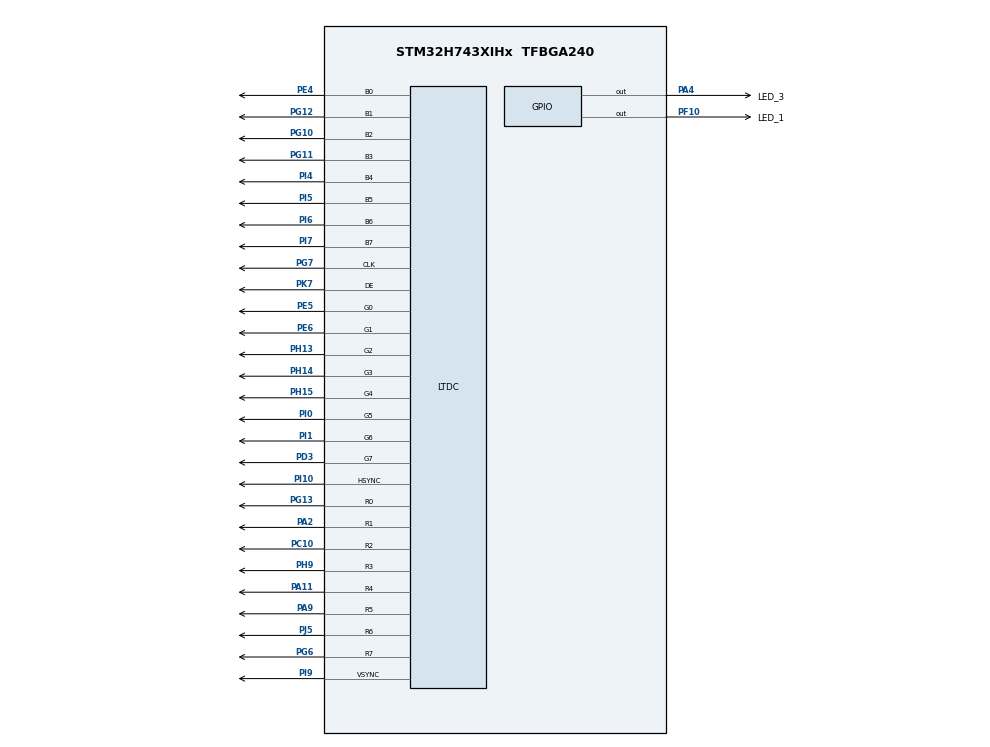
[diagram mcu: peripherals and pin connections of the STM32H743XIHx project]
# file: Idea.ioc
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FREERTOS.Tasks01=LED_1Blinker,1,128,StartBlinking1,Default,NULL,Dynamic,NULL,NULL;LED_3Blinker,0,128,StartBlinking3,Default,NULL,Dynamic,NULL,NULL;ResetLED,-1,128,StartReset,Default,NULL,Dynamic,NULL,NULL
FREERTOS.configENABLE_FPU=1
FREERTOS.configUSE_TIMERS=0
Mcu.Family=STM32H7
Mcu.Name=STM32H743XIHx
Mcu.Package=TFBGA240
NVIC.PriorityGroup=NVIC_PRIORITYGROUP_4
NVIC.TIM1_UP_IRQn=true\:15\:0\:false\:false\:true\:false\:false\:true\:true
NVIC.TimeBase=TIM1_UP_IRQn
NVIC.TimeBaseIP=TIM1
PA11.Mode=RGB888
PA11.Signal=LTDC_R4
PA2.Mode=RGB888
PA2.Signal=LTDC_R1
PA4.GPIO_Label=LED_3
PA4.Signal=GPIO_Output
PA9.Mode=RGB888
PA9.Signal=LTDC_R5
PC10.Mode=RGB888
PC10.Signal=LTDC_R2
PD3.Mode=RGB888
PD3.Signal=LTDC_G7
PE4.Mode=RGB888
PE4.Signal=LTDC_B0
PE5.Mode=RGB888
PE5.Signal=LTDC_G0
PE6.Mode=RGB888
PE6.Signal=LTDC_G1
PF10.GPIO_Label=LED_1
PF10.Signal=GPIO_Output
PG10.Mode=RGB888
PG10.Signal=LTDC_B2
PG11.Mode=RGB888
PG11.Signal=LTDC_B3
PG12.Mode=RGB888
PG12.Signal=LTDC_B1
PG13.Mode=RGB888
PG13.Signal=LTDC_R0
PG6.Mode=RGB888
PG6.Signal=LTDC_R7
PG7.Mode=RGB888
PG7.Signal=LTDC_CLK
PH13.Mode=RGB888
PH13.Signal=LTDC_G2
PH14.Mode=RGB888
PH14.Signal=LTDC_G3
PH15.Mode=RGB888
PH15.Signal=LTDC_G4
PH9.Mode=RGB888
PH9.Signal=LTDC_R3
PI0.Mode=RGB888
PI0.Signal=LTDC_G5
PI1.Mode=RGB888
PI1.Signal=LTDC_G6
PI10.Mode=RGB888
PI10.Signal=LTDC_HSYNC
PI4.Mode=RGB888
PI4.Signal=LTDC_B4
PI5.Mode=RGB888
PI5.Signal=LTDC_B5
PI6.Mode=RGB888
PI6.Signal=LTDC_B6
PI7.Mode=RGB888
PI7.Signal=LTDC_B7
PI9.Mode=RGB888
PI9.Signal=LTDC_VSYNC
PJ5.Mode=RGB888
PJ5.Signal=LTDC_R6
PK7.Mode=RGB888
PK7.Signal=LTDC_DE
ProjectManager.HeapSize=0x200
ProjectManager.StackSize=0x400
ProjectManager.TargetToolchain=STM32CubeIDE
RCC.ADCFreq_Value=75000000
RCC.APB1Freq_Value=75000000
RCC.APB2Freq_Value=18750000
RCC.APB3Freq_Value=75000000
RCC.APB4Freq_Value=75000000
RCC.CortexFreq_Value=75000000
RCC.D2PPRE2=RCC_APB2_DIV4
RCC.DIVM1=4
RCC.DIVM2=4
RCC.DIVM3=1
RCC.DIVN1=9
RCC.DIVN2=9
RCC.DIVN3=4
RCC.DIVQ1=1
RCC.HCLKFreq_Value=75000000
RCC.PLL2FRACN=3072
RCC.PLL3FRACN=0
RCC.PLLFRACN=3072
RCC.PWR_Regulator_Voltage_Scale=PWR_REGULATOR_VOLTAGE_SCALE1
RCC.SYSCLKFreq_VALUE=75000000
RCC.SYSCLKSource=RCC_SYSCLKSOURCE_PLLCLK
RCC.USBCLockSelection=RCC_USBCLKSOURCE_HSI48
RCC.USBFreq_Value=48000000
VP_FREERTOS_VS_CMSIS_V1.Mode=CMSIS_V1
VP_RNG_VS_RNG.Mode=RNG_Activate
VP_SYS_VS_tim1.Mode=TIM1
board=STM32H743I-EVAL2

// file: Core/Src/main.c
/* USER CODE BEGIN Header */
/**
  ******************************************************************************
  * @file           : main.c
  * @brief          : Main program body
  ******************************************************************************
  * @attention
  *
  * Copyright (c) 2023 STMicroelectronics.
  * All rights reserved.
  *
  * This software is licensed under terms that can be found in the LICENSE file
  * in the root directory of this software component.
  * If no LICENSE file comes with this software, it is provided AS-IS.
  *
  ******************************************************************************
  */
/* USER CODE END Header */
#include "main.h"
#include "cmsis_os.h"

LTDC_HandleTypeDef hltdc;

RNG_HandleTypeDef hrng;

osThreadId LED_1BlinkerHandle;
osThreadId LED_3BlinkerHandle;
osThreadId ResetLEDHandle;
osThreadId SetLEDHandle;

void SystemClock_Config(void);
static void MX_GPIO_Init(void);
static void MX_LTDC_Init(void);
static void MX_RNG_Init(void);
void StartBlinking1(void const * argument);
void StartBlinking3(void const * argument);
void StartReset(void const * argument);
void StartSet(void const * argument);

int main(void)
{

  /* MCU Configuration--------------------------------------------------------*/

  /* Reset of all peripherals, Initializes the Flash interface and the Systick. */
  HAL_Init();

  /* Configure the system clock */
  SystemClock_Config();

  /* Initialize all configured peripherals */
  MX_GPIO_Init();
  MX_LTDC_Init();
  MX_RNG_Init();

  /* Create the thread(s) */
  /* definition and creation of LED_1Blinker */
  osThreadDef(LED_1Blinker, StartBlinking1, osPriorityNormal, 0, 128);
  LED_1BlinkerHandle = osThreadCreate(osThread(LED_1Blinker), NULL);

  /* definition and creation of LED_3Blinker */
  osThreadDef(LED_3Blinker, StartBlinking3, osPriorityNormal, 0, 128);
  LED_3BlinkerHandle = osThreadCreate(osThread(LED_3Blinker), NULL);

  /* definition and creation of ResetLED */
  osThreadDef(ResetLED, StartReset, osPriorityBelowNormal, 0, 128);
  ResetLEDHandle = osThreadCreate(osThread(ResetLED), NULL);

  /* definition and creation of SetLED */
  osThreadDef(SetLED, StartSet, osPriorityBelowNormal, 0, 128);
  SetLEDHandle = osThreadCreate(osThread(SetLED), NULL);

  /* Start scheduler */
  osKernelStart();

  /* We should never get here as control is now taken by the scheduler */
  /* Infinite loop */
  while (1)
  {

  }
}

void SystemClock_Config(void)
{
  RCC_OscInitTypeDef RCC_OscInitStruct = {0};
  RCC_ClkInitTypeDef RCC_ClkInitStruct = {0};

  /** Supply configuration update enable
  */
  HAL_PWREx_ConfigSupply(PWR_LDO_SUPPLY);

  /** Configure the main internal regulator output voltage
  */
  __HAL_PWR_VOLTAGESCALING_CONFIG(PWR_REGULATOR_VOLTAGE_SCALE1);

  while(!__HAL_PWR_GET_FLAG(PWR_FLAG_VOSRDY)) {}

  /** Macro to configure the PLL clock source
  */
  __HAL_RCC_PLL_PLLSOURCE_CONFIG(RCC_PLLSOURCE_HSI);

  /** Initializes the RCC Oscillators according to the specified parameters
  * in the RCC_OscInitTypeDef structure.
  */
  RCC_OscInitStruct.OscillatorType = RCC_OSCILLATORTYPE_HSI48|RCC_OSCILLATORTYPE_HSI;
  RCC_OscInitStruct.HSIState = RCC_HSI_DIV1;
  RCC_OscInitStruct.HSICalibrationValue = RCC_HSICALIBRATION_DEFAULT;
  RCC_OscInitStruct.HSI48State = RCC_HSI48_ON;
  RCC_OscInitStruct.PLL.PLLState = RCC_PLL_ON;
  RCC_OscInitStruct.PLL.PLLSource = RCC_PLLSOURCE_HSI;
  RCC_OscInitStruct.PLL.PLLM = 4;
  RCC_OscInitStruct.PLL.PLLN = 9;
  RCC_OscInitStruct.PLL.PLLP = 2;
  RCC_OscInitStruct.PLL.PLLQ = 1;
  RCC_OscInitStruct.PLL.PLLR = 2;
  RCC_OscInitStruct.PLL.PLLRGE = RCC_PLL1VCIRANGE_3;
  RCC_OscInitStruct.PLL.PLLVCOSEL = RCC_PLL1VCOMEDIUM;
  RCC_OscInitStruct.PLL.PLLFRACN = 3072;
  if (HAL_RCC_OscConfig(&RCC_OscInitStruct) != HAL_OK)
  {
    Error_Handler();
  }

  /** Initializes the CPU, AHB and APB buses clocks
  */
  RCC_ClkInitStruct.ClockType = RCC_CLOCKTYPE_HCLK|RCC_CLOCKTYPE_SYSCLK
                              |RCC_CLOCKTYPE_PCLK1|RCC_CLOCKTYPE_PCLK2
                              |RCC_CLOCKTYPE_D3PCLK1|RCC_CLOCKTYPE_D1PCLK1;
  RCC_ClkInitStruct.SYSCLKSource = RCC_SYSCLKSOURCE_PLLCLK;
  RCC_ClkInitStruct.SYSCLKDivider = RCC_SYSCLK_DIV1;
  RCC_ClkInitStruct.AHBCLKDivider = RCC_HCLK_DIV1;
  RCC_ClkInitStruct.APB3CLKDivider = RCC_APB3_DIV1;
  RCC_ClkInitStruct.APB1CLKDivider = RCC_APB1_DIV1;
  RCC_ClkInitStruct.APB2CLKDivider = RCC_APB2_DIV4;
  RCC_ClkInitStruct.APB4CLKDivider = RCC_APB4_DIV1;

  if (HAL_RCC_ClockConfig(&RCC_ClkInitStruct, FLASH_LATENCY_1) != HAL_OK)
  {
    Error_Handler();
  }
}

static void MX_LTDC_Init(void)
{

  LTDC_LayerCfgTypeDef pLayerCfg = {0};
  LTDC_LayerCfgTypeDef pLayerCfg1 = {0};

  hltdc.Instance = LTDC;
  hltdc.Init.HSPolarity = LTDC_HSPOLARITY_AL;
  hltdc.Init.VSPolarity = LTDC_VSPOLARITY_AL;
  hltdc.Init.DEPolarity = LTDC_DEPOLARITY_AL;
  hltdc.Init.PCPolarity = LTDC_PCPOLARITY_IPC;
  hltdc.Init.HorizontalSync = 7;
  hltdc.Init.VerticalSync = 3;
  hltdc.Init.AccumulatedHBP = 14;
  hltdc.Init.AccumulatedVBP = 5;
  hltdc.Init.AccumulatedActiveW = 654;
  hltdc.Init.AccumulatedActiveH = 485;
  hltdc.Init.TotalWidth = 660;
  hltdc.Init.TotalHeigh = 487;
  hltdc.Init.Backcolor.Blue = 0;
  hltdc.Init.Backcolor.Green = 0;
  hltdc.Init.Backcolor.Red = 0;
  if (HAL_LTDC_Init(&hltdc) != HAL_OK)
  {
    Error_Handler();
  }
  pLayerCfg.WindowX0 = 0;
  pLayerCfg.WindowX1 = 0;
  pLayerCfg.WindowY0 = 0;
  pLayerCfg.WindowY1 = 0;
  pLayerCfg.PixelFormat = LTDC_PIXEL_FORMAT_ARGB8888;
  pLayerCfg.Alpha = 0;
  pLayerCfg.Alpha0 = 0;
  pLayerCfg.BlendingFactor1 = LTDC_BLENDING_FACTOR1_CA;
  pLayerCfg.BlendingFactor2 = LTDC_BLENDING_FACTOR2_CA;
  pLayerCfg.FBStartAdress = 0;
  pLayerCfg.ImageWidth = 0;
  pLayerCfg.ImageHeight = 0;
  pLayerCfg.Backcolor.Blue = 0;
  pLayerCfg.Backcolor.Green = 0;
  pLayerCfg.Backcolor.Red = 0;
  if (HAL_LTDC_ConfigLayer(&hltdc, &pLayerCfg, 0) != HAL_OK)
  {
    Error_Handler();
  }
  pLayerCfg1.WindowX0 = 0;
  pLayerCfg1.WindowX1 = 0;
  pLayerCfg1.WindowY0 = 0;
  pLayerCfg1.WindowY1 = 0;
  pLayerCfg1.PixelFormat = LTDC_PIXEL_FORMAT_ARGB8888;
  pLayerCfg1.Alpha = 0;
  pLayerCfg1.Alpha0 = 0;
  pLayerCfg1.BlendingFactor1 = LTDC_BLENDING_FACTOR1_CA;
  pLayerCfg1.BlendingFactor2 = LTDC_BLENDING_FACTOR2_CA;
  pLayerCfg1.FBStartAdress = 0;
  pLayerCfg1.ImageWidth = 0;
  pLayerCfg1.ImageHeight = 0;
  pLayerCfg1.Backcolor.Blue = 0;
  pLayerCfg1.Backcolor.Green = 0;
  pLayerCfg1.Backcolor.Red = 0;
  if (HAL_LTDC_ConfigLayer(&hltdc, &pLayerCfg1, 1) != HAL_OK)
  {
    Error_Handler();
  }

}

static void MX_RNG_Init(void)
{

  hrng.Instance = RNG;
  hrng.Init.ClockErrorDetection = RNG_CED_ENABLE;
  if (HAL_RNG_Init(&hrng) != HAL_OK)
  {
    Error_Handler();
  }

}

static void MX_GPIO_Init(void)
{
  GPIO_InitTypeDef GPIO_InitStruct = {0};

  /* GPIO Ports Clock Enable */
  __HAL_RCC_GPIOI_CLK_ENABLE();
  __HAL_RCC_GPIOG_CLK_ENABLE();
  __HAL_RCC_GPIOC_CLK_ENABLE();
  __HAL_RCC_GPIOD_CLK_ENABLE();
  __HAL_RCC_GPIOH_CLK_ENABLE();
  __HAL_RCC_GPIOE_CLK_ENABLE();
  __HAL_RCC_GPIOK_CLK_ENABLE();
  __HAL_RCC_GPIOA_CLK_ENABLE();
  __HAL_RCC_GPIOF_CLK_ENABLE();
  __HAL_RCC_GPIOJ_CLK_ENABLE();

  /*Configure GPIO pin Output Level */
  HAL_GPIO_WritePin(LED_1_GPIO_Port, LED_1_Pin, GPIO_PIN_RESET);

  /*Configure GPIO pin Output Level */
  HAL_GPIO_WritePin(LED_3_GPIO_Port, LED_3_Pin, GPIO_PIN_RESET);

  /*Configure GPIO pin : LED_1_Pin */
  GPIO_InitStruct.Pin = LED_1_Pin;
  GPIO_InitStruct.Mode = GPIO_MODE_OUTPUT_PP;
  GPIO_InitStruct.Pull = GPIO_NOPULL;
  GPIO_InitStruct.Speed = GPIO_SPEED_FREQ_LOW;
  HAL_GPIO_Init(LED_1_GPIO_Port, &GPIO_InitStruct);

  /*Configure GPIO pin : LED_3_Pin */
  GPIO_InitStruct.Pin = LED_3_Pin;
  GPIO_InitStruct.Mode = GPIO_MODE_OUTPUT_PP;
  GPIO_InitStruct.Pull = GPIO_NOPULL;
  GPIO_InitStruct.Speed = GPIO_SPEED_FREQ_LOW;
  HAL_GPIO_Init(LED_3_GPIO_Port, &GPIO_InitStruct);

}

void StartBlinking1(void const * argument)
{
  /* USER CODE BEGIN 5 */
  /* Infinite loop */
  for(;;)
  {
	HAL_GPIO_TogglePin(GPIOF,LED_1_Pin);
    osDelay(125);
  }
  /* USER CODE END 5 */
}

void StartBlinking3(void const * argument)
{
  /* USER CODE BEGIN StartBlinking3 */
  /* Infinite loop */
  for(;;)
  {
	HAL_GPIO_TogglePin(GPIOA,LED_3_Pin);
    osDelay(235);
  }
  /* USER CODE END StartBlinking3 */
}

void StartReset(void const * argument)
{
  /* USER CODE BEGIN StartReset */
  /* Infinite loop */
  for(;;)
  {
	if(HAL_GPIO_ReadPin(GPIOF,LED_1_Pin) != GPIO_PIN_SET){
		HAL_GPIO_TogglePin(GPIOF,LED_1_Pin);
	}
	if(HAL_GPIO_ReadPin(GPIOA,LED_3_Pin) != GPIO_PIN_SET){
			HAL_GPIO_TogglePin(GPIOA,LED_3_Pin);
	}
	//HAL_Delay(5000);
    osDelay(300);
  }
  /* USER CODE END StartReset */
}

void StartSet(void const * argument)
{
  /* USER CODE BEGIN StartReset */
  /* Infinite loop */
  for(;;)
  {
	if(HAL_GPIO_ReadPin(GPIOF,LED_1_Pin) != GPIO_PIN_RESET){
		HAL_GPIO_TogglePin(GPIOF,LED_1_Pin);
	}
	if(HAL_GPIO_ReadPin(GPIOA,LED_3_Pin) != GPIO_PIN_RESET){
			HAL_GPIO_TogglePin(GPIOA,LED_3_Pin);
	}
    osDelay(400);
  }
  /* USER CODE END StartReset */
}

void HAL_TIM_PeriodElapsedCallback(TIM_HandleTypeDef *htim)
{
  if (htim->Instance == TIM1) {
    HAL_IncTick();
  }
}

void Error_Handler(void)
{
  __disable_irq();
  while (1)
  {
  }
}
